# STM32L4A6 register map
File version: 1.0
CPU: CM4 r0p1, little endian, MPU, FPU, 4 interrupt priority bits
Registers are 32-bit, read-write, reset 0x0 unless marked. A register's access mark holds for its fields unless they carry their own. Offsets are from the block's base; [hi:lo] are bit positions.

## FIREWALL
Base 0x40011C00
0x00 CSSA — Code segment start address
  [23:8] ADD — code segment start address
0x04 CSL — Code segment length
  [21:8] LENG — code segment length
0x08 NVDSSA — Non-volatile data segment start address
  [23:8] ADD
0x0C NVDSL — Non-volatile data segment length
  [21:8] LENG
0x10 VDSSA — Volatile data segment start address
  [15:6] ADD
0x14 VDSL — Volatile data segment length
  [15:6] LENG — Non-volatile data segment length
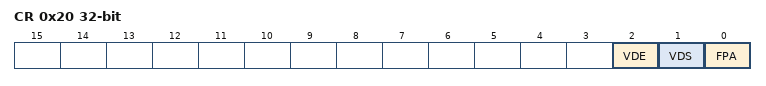
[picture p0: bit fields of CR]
0x20 CR — Configuration register
  [2] VDE — Volatile data execution
  [1] VDS — Volatile data shared
  [0] FPA — Firewall pre alarm

## DBGMCU — Debug support
Base 0xE0042000
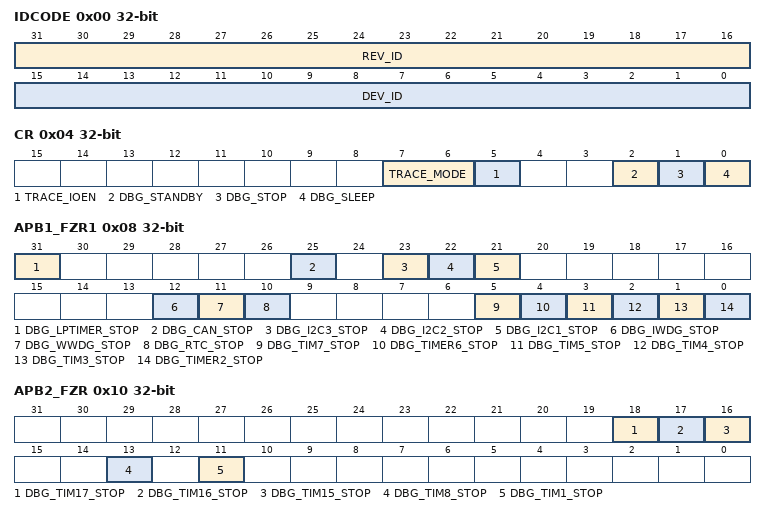
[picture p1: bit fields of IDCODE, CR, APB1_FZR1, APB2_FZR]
0x00 IDCODE ro — MCU Device ID Code Register
  [31:16] REV_ID — Revision Identifier
  [15:0] DEV_ID — Device Identifier
0x04 CR — Debug MCU Configuration Register
  [7:6] TRACE_MODE — Trace pin assignment control
  [5] TRACE_IOEN — Trace pin assignment control
  [2] DBG_STANDBY — Debug Standby Mode
  [1] DBG_STOP — Debug Stop Mode
  [0] DBG_SLEEP — Debug Sleep Mode
0x08 APB1_FZR1 — APB Low Freeze Register 1
  [31] DBG_LPTIMER_STOP — LPTIM1 counter stopped when core is halted
  [25] DBG_CAN_STOP — bxCAN stopped when core is halted
  [23] DBG_I2C3_STOP — I2C3 SMBUS timeout counter stopped when core is halted
  [22] DBG_I2C2_STOP — I2C2 SMBUS timeout mode stopped when core is halted
  [21] DBG_I2C1_STOP — I2C1 SMBUS timeout mode stopped when core is halted
  [12] DBG_IWDG_STOP — Debug Independent Wachdog stopped when Core is halted
  [11] DBG_WWDG_STOP — Debug Window Wachdog stopped when Core is halted
  [10] DBG_RTC_STOP — Debug RTC stopped when Core is halted
  [5] DBG_TIM7_STOP — TIM7 counter stopped when core is halted
  [4] DBG_TIMER6_STOP — Debug Timer 6 stopped when Core is halted
  [3] DBG_TIM5_STOP — TIM5 counter stopped when core is halted
  [2] DBG_TIM4_STOP — TIM4 counter stopped when core is halted
  [1] DBG_TIM3_STOP — TIM3 counter stopped when core is halted
  [0] DBG_TIMER2_STOP — Debug Timer 2 stopped when Core is halted
0x0C APB1_FZR2 — APB Low Freeze Register 2
  [5] DBG_LPTIM2_STOP — LPTIM2 counter stopped when core is halted
0x10 APB2_FZR — APB High Freeze Register
  [18] DBG_TIM17_STOP — TIM17 counter stopped when core is halted
  [17] DBG_TIM16_STOP — TIM16 counter stopped when core is halted
  [16] DBG_TIM15_STOP — TIM15 counter stopped when core is halted
  [13] DBG_TIM8_STOP — TIM8 counter stopped when core is halted
  [11] DBG_TIM1_STOP — TIM1 counter stopped when core is halted

## QUADSPI — QuadSPI interface
Base 0xA0001000
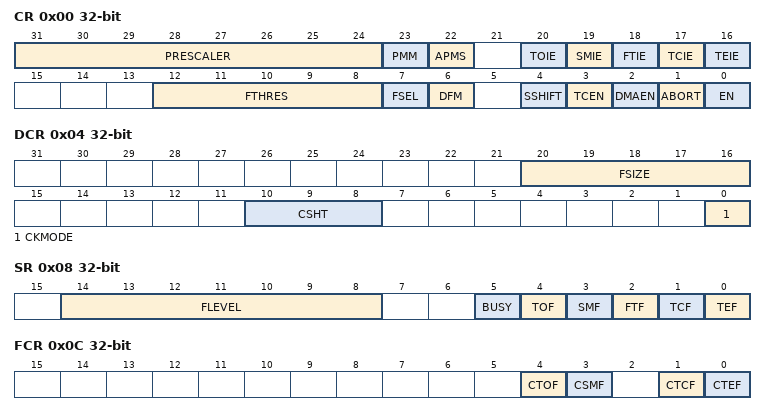
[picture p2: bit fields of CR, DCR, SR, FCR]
0x00 CR — control register
  [31:24] PRESCALER — Clock prescaler
  [23] PMM — Polling match mode
  [22] APMS — Automatic poll mode stop
  [20] TOIE — TimeOut interrupt enable
  [19] SMIE — Status match interrupt enable
  [18] FTIE — FIFO threshold interrupt enable
  [17] TCIE — Transfer complete interrupt enable
  [16] TEIE — Transfer error interrupt enable
  [12:8] FTHRES — IFO threshold level
  [7] FSEL — FLASH memory selection
  [6] DFM — Dual-flash mode
  [4] SSHIFT — Sample shift
  [3] TCEN — Timeout counter enable
  [2] DMAEN — DMA enable
  [1] ABORT — Abort request
  [0] EN — Enable
0x04 DCR — device configuration register
  [20:16] FSIZE — FLASH memory size
  [10:8] CSHT — Chip select high time
  [0] CKMODE — Mode 0 / mode 3
0x08 SR ro — status register
  [14:8] FLEVEL — FIFO level
  [5] BUSY
  [4] TOF — Timeout flag
  [3] SMF — Status match flag
  [2] FTF — FIFO threshold flag
  [1] TCF — Transfer complete flag
  [0] TEF — Transfer error flag
0x0C FCR — flag clear register
  [4] CTOF — Clear timeout flag
  [3] CSMF — Clear status match flag
  [1] CTCF — Clear transfer complete flag
  [0] CTEF — Clear transfer error flag
0x10 DLR — data length register
  [31:0] DL — Data length
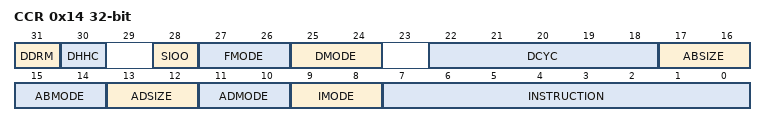
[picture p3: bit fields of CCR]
0x14 CCR — communication configuration register
  [31] DDRM — Double data rate mode
  [30] DHHC — DDR hold half cycle
  [28] SIOO — Send instruction only once mode
  [27:26] FMODE — Functional mode
  [25:24] DMODE — Data mode
  [22:18] DCYC — Number of dummy cycles
  [17:16] ABSIZE — Alternate bytes size
  [15:14] ABMODE — Alternate bytes mode
  [13:12] ADSIZE — Address size
  [11:10] ADMODE — Address mode
  [9:8] IMODE — Instruction mode
  [7:0] INSTRUCTION
0x18 AR — address register
  [31:0] ADDRESS
0x1C ABR
  [31:0] ALTERNATE
0x20 DR — data register
  [31:0] DATA
0x24 PSMKR — polling status mask register
  [31:0] MASK — Status mask
0x28 PSMAR — polling status match register
  [31:0] MATCH — Status match
0x2C PIR — polling interval register
  [15:0] INTERVAL — Polling interval
0x30 LPTR — low-power timeout register
  [15:0] TIMEOUT — Timeout period
